# XHSC_HC32F052 register map
Vendor: HDSC Co.Ltd; Series: ARMCM4; File version: 1.2
CPU: CM0 r0p0, little endian, no MPU, no FPU, 3 interrupt priority bits
Registers are 32-bit, read-write, reset 0x0 unless marked. A register's access mark holds for its fields unless they carry their own. Offsets are from the block's base; lines under a group give offsets from that group; [hi:lo] are bit positions; {n}, {i} and the like mark numbered series; 'fields as' and 'values as' point back to an identical list; <NAME> marks a mode.

## Memory map
0x40000000 LPUART0 size 0x1C — desc LPUART
0x40000400 I2C0 size 0x44 — desc I2C
0x40000800 SPI0 size 0x1C — desc SPI
0x40000C00 LPTIM size 0x18
0x40001080 IWDT size 0x14
0x40001400 RTC size 0x64
0x40001800 BTIM0 size 0x50 — desc BTIM
0x40001800 GTIM0 size 0x330 — desc GTIM
0x40001900 BTIM1 size 0x50 — desc BTIM
0x40001A00 BTIM2 size 0x50 — desc BTIM
0x40001C00 BTIM3 size 0x50 — desc BTIM
0x40001C00 GTIM1 size 0x330 — desc GTIM
0x40001D00 BTIM4 size 0x50 — desc BTIM
0x40001E00 BTIM5 size 0x50 — desc BTIM
0x40002000 GPIOAUX size 0x180
0x40002000 SYSCTRL size 0x48
0x40002400 VC0 size 0x20 — desc VC
0x40002410 VC1 size 0x20 — desc VC
0x40002480 LVD size 0x8
0x40002500 ADC size 0xCC
0x40002600 OPA size 0xC
0x40003000 ATIM0MODE0 size 0x34
0x40003000 ATIM0MODE1 size 0x40
0x40003000 ATIM0MODE23 size 0x5C
0x40003400 ATIM1MODE0 size 0x34
0x40003400 ATIM1MODE1 size 0x40
0x40003400 ATIM1MODE23 size 0x5C
0x40003800 ATIM2MODE0 size 0x34
0x40003800 ATIM2MODE1 size 0x40
0x40003800 ATIM2MODE23 size 0x5C
0x40004000 LPUART1 size 0x1C — desc LPUART
0x40004400 I2C1 size 0x44 — desc I2C
0x40004800 SPI1 size 0x1C — desc SPI
0x40004C00 I2CSLV size 0x5C
0x40005000 CTRIM size 0x2C
0x40005800 ATIM3MODE0 size 0x34
0x40005800 ATIM3MODE1 size 0x40
0x40005800 ATIM3MODE23 size 0x64
0x40006000 USART0 size 0xF4 — desc USART
0x40006400 USART1 size 0xF4 — desc USART
0x40006800 WWDT size 0xC
0x40020000 FLASH size 0x38
0x40020400 RAM size 0x10
0x40020800 CRC size 0x84
0x40020C00 GPIOA size 0x50 — desc GPIO
0x40021000 DMAC size 0x70
0x40021800 EAU size 0x14
0x40021C00 GPIOB size 0x50 — desc GPIO
0x40022000 GPIOC size 0x50 — desc GPIO
0x40022400 GPIOD size 0x50 — desc GPIO
0x40030000 CAN size 0xCA

## Interrupts
0 PORTA (GPIOA) — PORTA interrupt
1 PORTB (GPIOB) — PORTB interrupt
2 PORTC (GPIOC) — PORTC interrupt
3 PORTD (GPIOD) — PORTD interrupt
4 DMAC — DMAC interrupt
6 USART0 — USART0 interrupt
7 USART1 — USART1 interrupt
8 LPUART0 — LPUART0 interrupt
9 LPUART1 — LPUART1 interrupt
10 SPI0 — SPI0 interrupt
11 SPI1 — SPI1 interrupt
12 I2C0 — I2C0 interrupt
13 I2C1 — I2C1 interrupt
17 LPTIM — LPTIM interrupt
18 GTIM0_BTIM0_1_2 (BTIM{n} (n=0..2), GTIM0) — GTIM0_BTIM0_1_2 interrupt
19 GTIM1_BTIM3_4_5 (BTIM{n} (n=3..5), GTIM1) — GTIM1_BTIM3_4_5 interrupt
20 I2CSLV — I2CSLV interrupt
21 WWDT — WWDT interrupt
22 IWDT — IWDT interrupt
23 RTC — RTC interrupt
24 ADC — ADC interrupt
26 VC0_VC1_LVD (LVD, VC0, VC1) — VC0_VC1_LVD interrupt
28 CAN — CAN interrupt
30 FLASH_RAM (FLASH, RAM) — FLASH_RAM interrupt
31 CTRIM — CTRIM interrupt

## ADC
Base 0x40002500
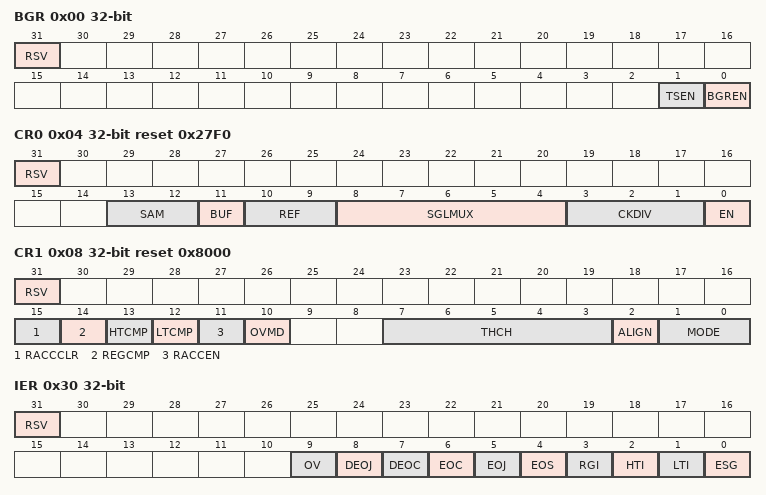
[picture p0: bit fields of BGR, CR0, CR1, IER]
0x00 BGR (reset mask 0x3)
  [31] RSV, [1] TSEN, [0] BGREN
0x04 CR0 reset 0x27F0 (reset mask 0x3FFF)
  [31] RSV, [13:12] SAM, [11] BUF, [10:9] REF, [8:4] SGLMUX, [3:1] CKDIV, [0] EN
0x08 CR1 reset 0x8000 (reset mask 0xFCFF)
  [31] RSV, [15] RACCCLR, [14] REGCMP, [13] HTCMP, [12] LTCMP, [11] RACCEN, [10] OVMD, [7:3] THCH, [2] ALIGN, [1:0] MODE
0x30 IER (reset mask 0x3FF)
  [31] RSV, [9] OV, [8] DEOJ, [7] DEOC, [6] EOC, [5] EOJ, [4] EOS, [3] RGI, [2] HTI, [1] LTI, [0] ESG
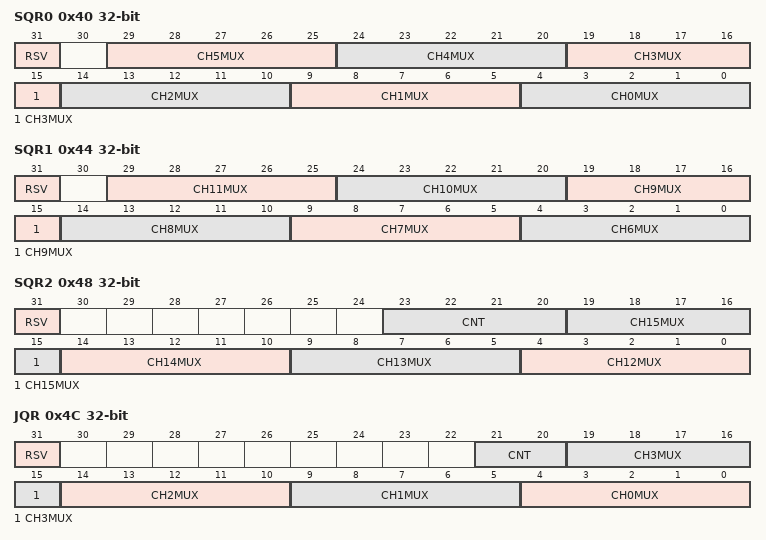
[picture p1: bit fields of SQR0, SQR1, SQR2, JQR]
0x40 SQR0 (reset mask 0x3FFFFFFF)
  [31] RSV, [5n+4:5n] CH{n}MUX (n=0..5)
0x44 SQR1 (reset mask 0x3FFFFFFF)
  [31] RSV, [5n-26:5n-30] CH{n}MUX (n=6..11)
0x48 SQR2 (reset mask 0xFFFFFF)
  [31] RSV, [23:20] CNT, [5n-56:5n-60] CH{n}MUX (n=12..15)
0x4C JQR (reset mask 0x3FFFFF)
  [31] RSV, [21:20] CNT, [5n+4:5n] CH{n}MUX (n=0..3)
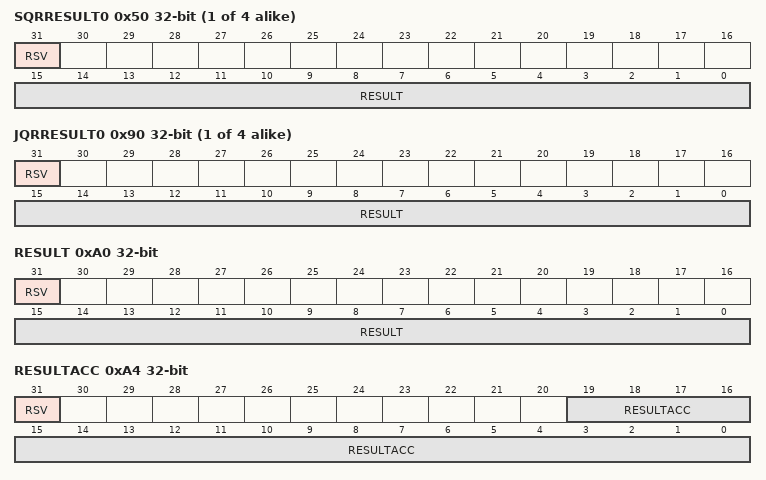
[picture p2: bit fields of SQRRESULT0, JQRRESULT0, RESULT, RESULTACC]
{0x50+4i} SQRRESULT{i} (reset mask 0xFFFF) (i=0..3)
  [31] RSV, [15:0] RESULT ro
{0x90+4i} JQRRESULT{i} (reset mask 0xFFFF) (i=0..3)
  [31] RSV, [15:0] RESULT ro
0xA0 RESULT (reset mask 0xFFFF)
  [31] RSV, [15:0] RESULT ro
0xA4 RESULTACC (reset mask 0xFFFFF)
  [31] RSV, [19:0] RESULTACC ro
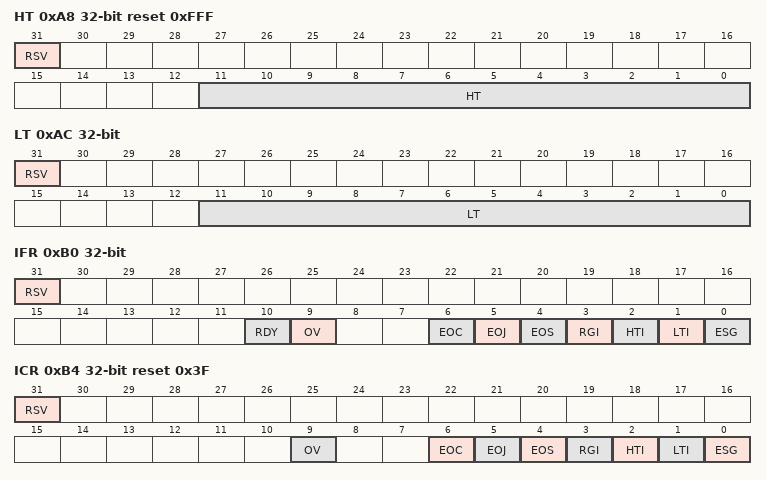
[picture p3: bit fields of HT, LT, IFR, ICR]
0xA8 HT reset 0xFFF (reset mask 0xFFF)
  [31] RSV, [11:0] HT
0xAC LT (reset mask 0xFFF)
  [31] RSV, [11:0] LT
0xB0 IFR (reset mask 0x27F)
  [31] RSV, [10] RDY ro, [9] OV ro, [6] EOC ro, [5] EOJ ro, [4] EOS ro, [3] RGI ro, [2] HTI ro, [1] LTI ro, [0] ESG ro
0xB4 ICR reset 0x3F (reset mask 0x27F)
  [31] RSV, [9] OV, [6] EOC, [5] EOJ, [4] EOS, [3] RGI, [2] HTI, [1] LTI, [0] ESG
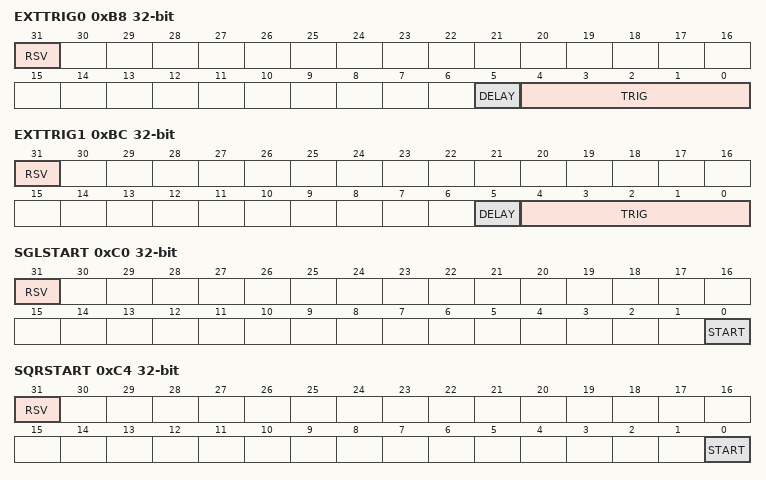
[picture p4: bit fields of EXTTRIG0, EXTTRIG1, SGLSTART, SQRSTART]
0xB8 EXTTRIG0 (reset mask 0x3F)
  [31] RSV, [5] DELAY, [4:0] TRIG
0xBC EXTTRIG1 (reset mask 0x3F)
  [31] RSV, [5] DELAY, [4:0] TRIG
0xC0 SGLSTART (reset mask 0x1)
  [31] RSV, [0] START
0xC4 SQRSTART (reset mask 0x1)
  [31] RSV, [0] START
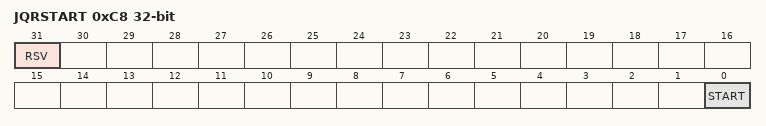
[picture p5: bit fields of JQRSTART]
0xC8 JQRSTART (reset mask 0x1)
  [31] RSV, [0] START
